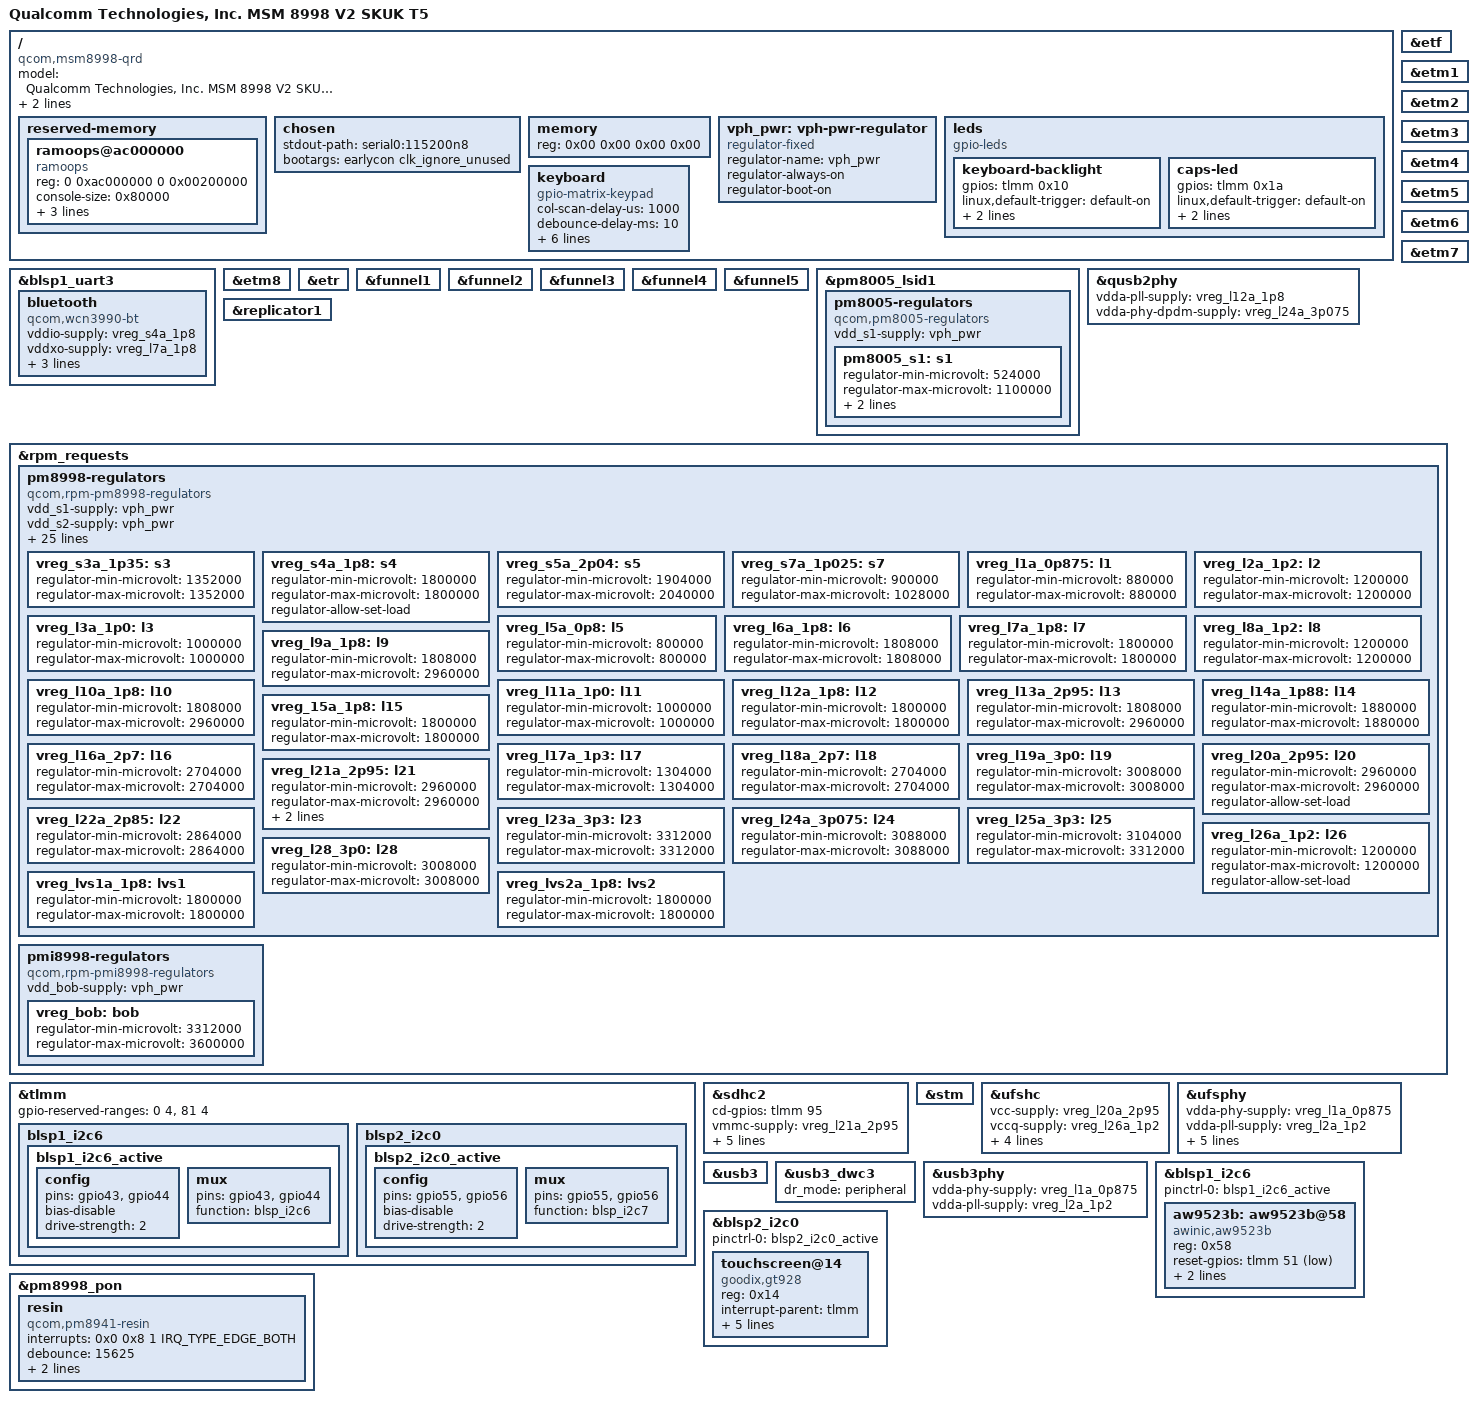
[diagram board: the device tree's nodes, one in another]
// SPDX-License-Identifier: GPL-2.0
/* Copyright (c) 2016, The Linux Foundation. All rights reserved. */

/dts-v1/;

#include "msm8998.dtsi"
#include "pm8998.dtsi"
#include "pmi8998.dtsi"
#include "pm8005.dtsi"
#include <dt-bindings/input/input.h>

/ {
	model = "Qualcomm Technologies, Inc. MSM 8998 V2 SKUK T5";
	compatible = "qcom,msm8998-qrd", "qcom,msm8998", "qcom,qrd";
    qcom,board-id = <0x02000b 0x10>;
	qcom,msm-id = <0x124 0x20000>;

    reserved-memory {
        #address-cells = <2>;
        #size-cells = <2>;
        ranges;

        ramoops@ac000000{
            compatible = "ramoops";
            reg = <0 0xac000000 0 0x00200000>;

            console-size = <0x80000>;
            pmsg-size    = <0x00040000>;
            record-size = <0x8000>;
            ftrace-size = <0x20000>;
            status = "okay";
        };

    };
	chosen {
		stdout-path = "serial0:115200n8";
/* System will panic on boot if we don't have clk_ignore_unused */
		bootargs = "earlycon clk_ignore_unused";
	};
/*
An empty /memory node is needed because boot-loader can only fill an empty node, it can't create a new memory node
*/
	memory {
		device_type = "memory";
		reg = < 0x00 0x00 0x00 0x00 >;
	};

	vph_pwr: vph-pwr-regulator {
		compatible = "regulator-fixed";
		regulator-name = "vph_pwr";
		regulator-always-on;
		regulator-boot-on;
	};

             leds {
                 compatible = "gpio-leds";
                 keyboard-backlight {
                     gpios = <&tlmm 0x10 GPIO_ACTIVE_HIGH>;
                     linux,default-trigger = "default-on";
                     function = "power";
                     default-state = "off";
                 };
                 caps-led {
                     gpios = <&tlmm 0x1a GPIO_ACTIVE_HIGH>;
                     linux,default-trigger = "default-on";
                     function = "power";
                     default-state = "off";
                 };
             };

    keyboard {
        compatible = "gpio-matrix-keypad";

        col-scan-delay-us = <1000>;
        debounce-delay-ms = <10>;
        wakeup-source;

        row-gpios = <&aw9523b  0 0
                     &aw9523b  1 0
                     &aw9523b  2 0>;
                     /*&aw9523b  2 0
                     &aw9523b  3 0
                     &aw9523b  4 0
                     &aw9523b  5 0
                     &aw9523b  6 0
                     &aw9523b  7 0>;*/
        col-gpios = <&aw9523b  8 0
                     &aw9523b  9 0
                     &aw9523b 10 0>;
                     /*&aw9523b 11 0
                     &aw9523b 12 0
                     &aw9523b 13 0
                     &aw9523b 14 0
                     &aw9523b 15 0>;*/
        gpio-activelow;

        linux,keymap = <
            MATRIX_KEY(0, 0, KEY_F1)    /* S2 */
            MATRIX_KEY(0, 1, KEY_F2)    /* S3 */
            MATRIX_KEY(0, 2, KEY_F3)    /* S4 */
            MATRIX_KEY(1, 0, KEY_F4)    /* S5 */
            MATRIX_KEY(1, 1, KEY_F5)    /* S6 */
            MATRIX_KEY(1, 2, KEY_F6)    /* S7 */
            MATRIX_KEY(2, 0, KEY_F7)    /* S8 */
            MATRIX_KEY(2, 1, KEY_F8)    /* S8 */
            MATRIX_KEY(2, 2, KEY_F9)    /* S8 */
>;
};

};

&blsp1_uart3 {
	status = "okay";

	bluetooth {
		compatible = "qcom,wcn3990-bt";

		vddio-supply = <&vreg_s4a_1p8>;
		vddxo-supply = <&vreg_l7a_1p8>;
		vddrf-supply = <&vreg_l17a_1p3>;
		vddch0-supply = <&vreg_l25a_3p3>;
		max-speed = <3200000>;
	};
};
&etf {
	status = "okay";
};

&etm1 {
	status = "okay";
};

&etm2 {
	status = "okay";
};

&etm3 {
	status = "okay";
};

&etm4 {
	status = "okay";
};

&etm5 {
	status = "okay";
};

&etm6 {
	status = "okay";
};

&etm7 {
	status = "okay";
};

&etm8 {
	status = "okay";
};

&etr {
	status = "okay";
};

&funnel1 {
	status = "okay";
};

&funnel2 {
	status = "okay";
};

&funnel3 {
	status = "okay";
};

&funnel4 {
	status = "okay";
};

&funnel5 {
	status = "okay";
};

&pm8005_lsid1 {
	pm8005-regulators {
		compatible = "qcom,pm8005-regulators";

		vdd_s1-supply = <&vph_pwr>;

		pm8005_s1: s1 { /* VDD_GFX supply */
			regulator-min-microvolt = <524000>;
			regulator-max-microvolt = <1100000>;
			regulator-enable-ramp-delay = <500>;

			/* hack until we rig up the gpu consumer */
			regulator-always-on;
		};
	};
};

&qusb2phy {
	status = "okay";

	vdda-pll-supply = <&vreg_l12a_1p8>;
	vdda-phy-dpdm-supply = <&vreg_l24a_3p075>;
};

&replicator1 {
	status = "okay";
};

&rpm_requests {
	pm8998-regulators {
		compatible = "qcom,rpm-pm8998-regulators";

		vdd_s1-supply = <&vph_pwr>;
		vdd_s2-supply = <&vph_pwr>;
		vdd_s3-supply = <&vph_pwr>;
		vdd_s4-supply = <&vph_pwr>;
		vdd_s5-supply = <&vph_pwr>;
		vdd_s6-supply = <&vph_pwr>;
		vdd_s7-supply = <&vph_pwr>;
		vdd_s8-supply = <&vph_pwr>;
		vdd_s9-supply = <&vph_pwr>;
		vdd_s10-supply = <&vph_pwr>;
		vdd_s11-supply = <&vph_pwr>;
		vdd_s12-supply = <&vph_pwr>;
		vdd_s13-supply = <&vph_pwr>;
		vdd_l1_l27-supply = <&vreg_s7a_1p025>;
		vdd_l2_l8_l17-supply = <&vreg_s3a_1p35>;
		vdd_l3_l11-supply = <&vreg_s7a_1p025>;
		vdd_l4_l5-supply = <&vreg_s7a_1p025>;
		vdd_l6-supply = <&vreg_s5a_2p04>;
		vdd_l7_l12_l14_l15-supply = <&vreg_s5a_2p04>;
		vdd_l9-supply = <&vreg_bob>;
		vdd_l10_l23_l25-supply = <&vreg_bob>;
		vdd_l13_l19_l21-supply = <&vreg_bob>;
		vdd_l16_l28-supply = <&vreg_bob>;
		vdd_l18_l22-supply = <&vreg_bob>;
		vdd_l20_l24-supply = <&vreg_bob>;
		vdd_l26-supply = <&vreg_s3a_1p35>;
		vdd_lvs1_lvs2-supply = <&vreg_s4a_1p8>;

		vreg_s3a_1p35: s3 {
			regulator-min-microvolt = <1352000>;
			regulator-max-microvolt = <1352000>;
		};
		vreg_s4a_1p8: s4 {
			regulator-min-microvolt = <1800000>;
			regulator-max-microvolt = <1800000>;
			regulator-allow-set-load;
		};
		vreg_s5a_2p04: s5 {
			regulator-min-microvolt = <1904000>;
			regulator-max-microvolt = <2040000>;
		};
		vreg_s7a_1p025: s7 {
			regulator-min-microvolt = <900000>;
			regulator-max-microvolt = <1028000>;
		};
		vreg_l1a_0p875: l1 {
			regulator-min-microvolt = <880000>;
			regulator-max-microvolt = <880000>;
		};
		vreg_l2a_1p2: l2 {
			regulator-min-microvolt = <1200000>;
			regulator-max-microvolt = <1200000>;
		};
		vreg_l3a_1p0: l3 {
			regulator-min-microvolt = <1000000>;
			regulator-max-microvolt = <1000000>;
		};
		vreg_l5a_0p8: l5 {
			regulator-min-microvolt = <800000>;
			regulator-max-microvolt = <800000>;
		};
		vreg_l6a_1p8: l6 {
			regulator-min-microvolt = <1808000>;
			regulator-max-microvolt = <1808000>;
		};
		vreg_l7a_1p8: l7 {
			regulator-min-microvolt = <1800000>;
			regulator-max-microvolt = <1800000>;
		};
		vreg_l8a_1p2: l8 {
			regulator-min-microvolt = <1200000>;
			regulator-max-microvolt = <1200000>;
		};
		vreg_l9a_1p8: l9 {
			regulator-min-microvolt = <1808000>;
			regulator-max-microvolt = <2960000>;
		};
		vreg_l10a_1p8: l10 {
			regulator-min-microvolt = <1808000>;
			regulator-max-microvolt = <2960000>;
		};
		vreg_l11a_1p0: l11 {
			regulator-min-microvolt = <1000000>;
			regulator-max-microvolt = <1000000>;
		};
		vreg_l12a_1p8: l12 {
			regulator-min-microvolt = <1800000>;
			regulator-max-microvolt = <1800000>;
		};
		vreg_l13a_2p95: l13 {
			regulator-min-microvolt = <1808000>;
			regulator-max-microvolt = <2960000>;
		};
		vreg_l14a_1p88: l14 {
			regulator-min-microvolt = <1880000>;
			regulator-max-microvolt = <1880000>;
		};
		vreg_15a_1p8: l15 {
			regulator-min-microvolt = <1800000>;
			regulator-max-microvolt = <1800000>;
		};
		vreg_l16a_2p7: l16 {
			regulator-min-microvolt = <2704000>;
			regulator-max-microvolt = <2704000>;
		};
		vreg_l17a_1p3: l17 {
			regulator-min-microvolt = <1304000>;
			regulator-max-microvolt = <1304000>;
		};
		vreg_l18a_2p7: l18 {
			regulator-min-microvolt = <2704000>;
			regulator-max-microvolt = <2704000>;
		};
		vreg_l19a_3p0: l19 {
			regulator-min-microvolt = <3008000>;
			regulator-max-microvolt = <3008000>;
		};
		vreg_l20a_2p95: l20 {
			regulator-min-microvolt = <2960000>;
			regulator-max-microvolt = <2960000>;
			regulator-allow-set-load;
		};
		vreg_l21a_2p95: l21 {
			regulator-min-microvolt = <2960000>;
			regulator-max-microvolt = <2960000>;
			regulator-allow-set-load;
			regulator-system-load = <800000>;
		};
		vreg_l22a_2p85: l22 {
			regulator-min-microvolt = <2864000>;
			regulator-max-microvolt = <2864000>;
		};
		vreg_l23a_3p3: l23 {
			regulator-min-microvolt = <3312000>;
			regulator-max-microvolt = <3312000>;
		};
		vreg_l24a_3p075: l24 {
			regulator-min-microvolt = <3088000>;
			regulator-max-microvolt = <3088000>;
		};
		vreg_l25a_3p3: l25 {
			regulator-min-microvolt = <3104000>;
			regulator-max-microvolt = <3312000>;
		};
		vreg_l26a_1p2: l26 {
			regulator-min-microvolt = <1200000>;
			regulator-max-microvolt = <1200000>;
			regulator-allow-set-load;
		};
		vreg_l28_3p0: l28 {
			regulator-min-microvolt = <3008000>;
			regulator-max-microvolt = <3008000>;
		};

		vreg_lvs1a_1p8: lvs1 {
			regulator-min-microvolt = <1800000>;
			regulator-max-microvolt = <1800000>;
		};

		vreg_lvs2a_1p8: lvs2 {
			regulator-min-microvolt = <1800000>;
			regulator-max-microvolt = <1800000>;
		};

	};

	pmi8998-regulators {
		compatible = "qcom,rpm-pmi8998-regulators";

		vdd_bob-supply = <&vph_pwr>;

		vreg_bob: bob {
			regulator-min-microvolt = <3312000>;
			regulator-max-microvolt = <3600000>;
		};
	};
};

&tlmm {
	gpio-reserved-ranges = <0 4>, <81 4>;
};

&sdhc2 {
	status = "okay";
	cd-gpios = <&tlmm 95 GPIO_ACTIVE_HIGH>;

	vmmc-supply = <&vreg_l21a_2p95>;
	vqmmc-supply = <&vreg_l13a_2p95>;

	pinctrl-names = "default", "sleep";
	pinctrl-0 = <&sdc2_clk_on  &sdc2_cmd_on  &sdc2_data_on  &sdc2_cd_on>;
	pinctrl-1 = <&sdc2_clk_off &sdc2_cmd_off &sdc2_data_off &sdc2_cd_off>;
};

&stm {
	status = "okay";
};

&ufshc {
	vcc-supply = <&vreg_l20a_2p95>;
	vccq-supply = <&vreg_l26a_1p2>;
	vccq2-supply = <&vreg_s4a_1p8>;
	vcc-max-microamp = <750000>;
	vccq-max-microamp = <560000>;
	vccq2-max-microamp = <750000>;
};

&ufsphy {
	vdda-phy-supply = <&vreg_l1a_0p875>;
	vdda-pll-supply = <&vreg_l2a_1p2>;
	vddp-ref-clk-supply = <&vreg_l26a_1p2>;
	vdda-phy-max-microamp = <51400>;
	vdda-pll-max-microamp = <14600>;
	vddp-ref-clk-max-microamp = <100>;
	vddp-ref-clk-always-on;
};

&usb3 {
	status = "okay";
};

&usb3_dwc3 {
	dr_mode = "peripheral"; /* Force to peripheral until we have Type-C hooked up */
};

&usb3phy {
	status = "okay";

	vdda-phy-supply = <&vreg_l1a_0p875>;
	vdda-pll-supply = <&vreg_l2a_1p2>;
};

&blsp1_i2c6 {
    status = "okay";
    //NFC @ 0x28
    //keyboard over AW9523b @ 0x58
    // - reset &tlmm 51
    // - caps lock &tlmm 26 0
    // - irq &tlmm 50 0x2008
    pinctrl-names = "default";
    pinctrl-0 = <&blsp1_i2c6_active>;
    aw9523b: aw9523b@58 {
        #gpio-cells = <2>;
        compatible = "awinic,aw9523b";
        reg = <0x58>;
        reset-gpios = <&tlmm 51 GPIO_ACTIVE_LOW>;
        interrupt-parent = <&tlmm>;
        interrupts = <50 IRQ_TYPE_LEVEL_HIGH>;
    };
};

&blsp2_i2c0 {
    status = "okay";
    pinctrl-names = "default";
    pinctrl-0 = <&blsp2_i2c0_active>;

    //Touchscreen
	touchscreen@14 {
		compatible = "goodix,gt928"; // actually gt9286
		reg = <0x14>;
		//reset-gpios = <&tlmm 89 GPIO_ACTIVE_HIGH>, <&tlmm 81 GPIO_ACTIVE_HIGH>;
		interrupt-parent = <&tlmm>;
		interrupts = <125 IRQ_TYPE_LEVEL_HIGH>;
		irq-gpios = <&tlmm 125 GPIO_ACTIVE_HIGH>;
		touchscreen-size-x = <720>;
		touchscreen-size-y = <1440>;
        VDDIO-supply = <&vreg_l28_3p0>;
	};
};

&tlmm {
    blsp1_i2c6 {
        blsp1_i2c6_active: blsp1_i2c6_active {
            config {
                pins = "gpio43", "gpio44";
                bias-disable;           /* NO pull */
                drive-strength = <2>;  /* 16 mA */
            };
            mux {
                pins = "gpio43", "gpio44";
                function = "blsp_i2c6";
            };
        };
    };
    blsp2_i2c0 {
        blsp2_i2c0_active: blsp2_i2c0_active {
            config {
                pins = "gpio55", "gpio56";
                bias-disable;           /* NO pull */
                drive-strength = <2>;  /* 16 mA */
            };
            mux {
                pins = "gpio55", "gpio56";
                function = "blsp_i2c7";
            };
        };
    };
};

&pm8998_pon {
	resin {
		compatible = "qcom,pm8941-resin";
		interrupts = <0x0 0x8 1 IRQ_TYPE_EDGE_BOTH>;
		debounce = <15625>;
		bias-pull-up;
		linux,code = <KEY_VOLUMEDOWN>;
	};
};
